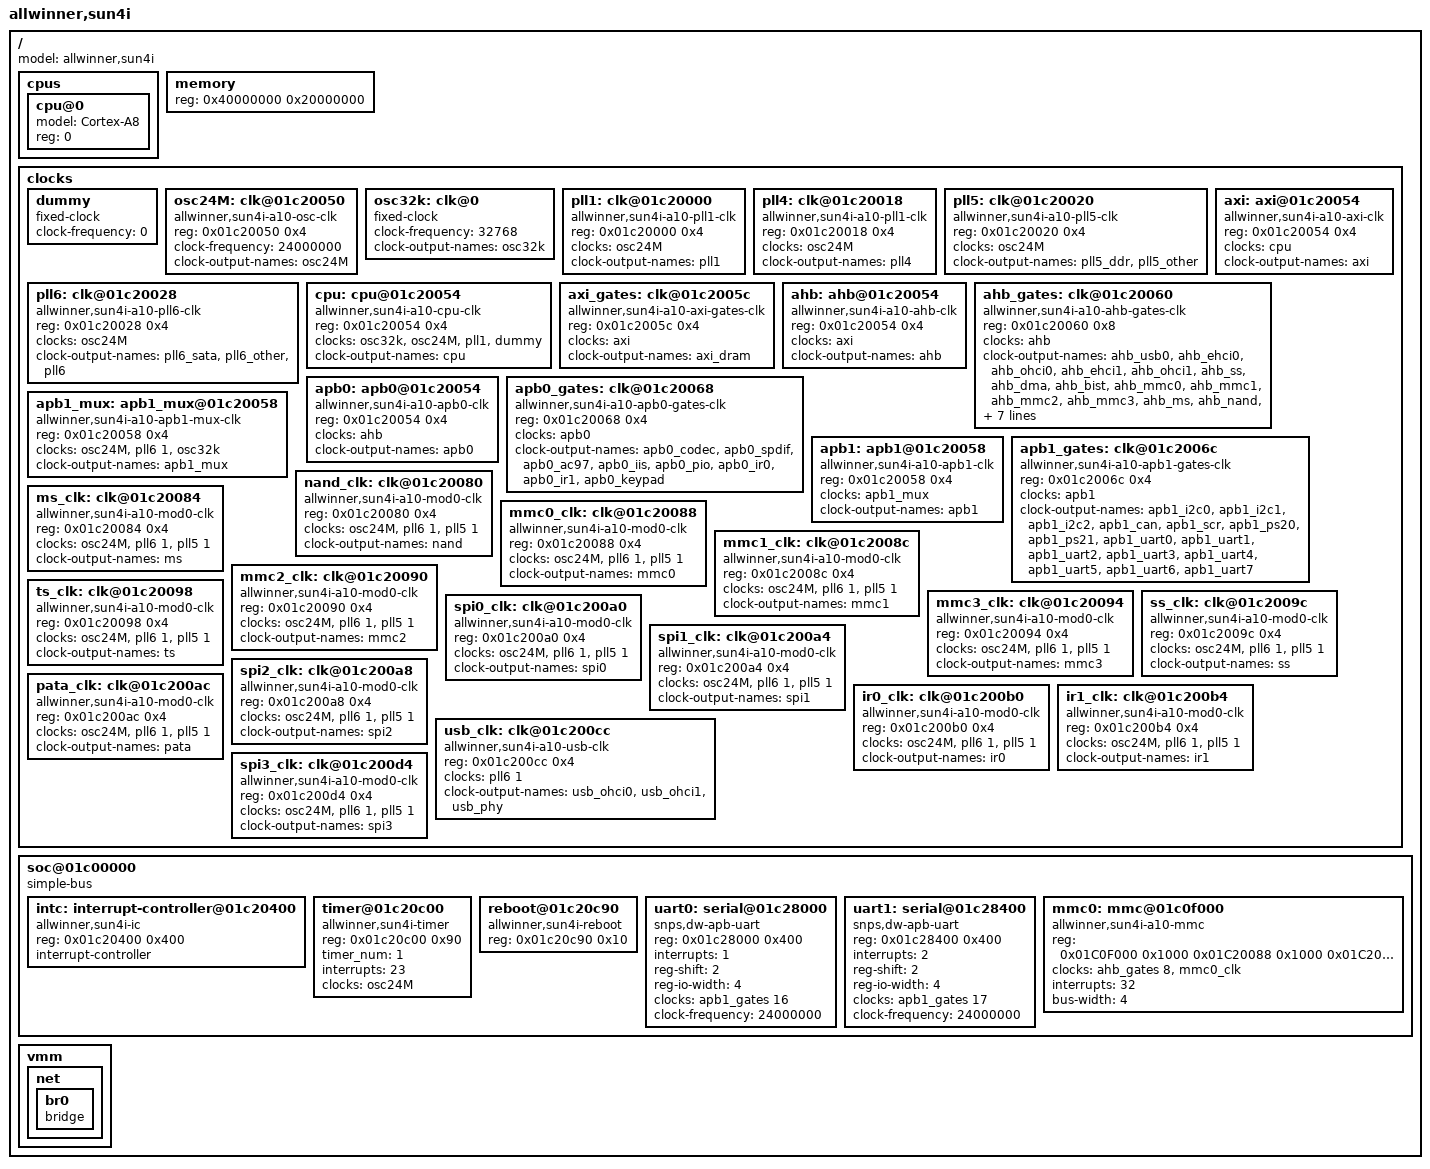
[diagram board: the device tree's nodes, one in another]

/ {
	#address-cells = <1>;
	#size-cells = <1>;
	model = "allwinner,sun4i";


	cpus {
		#address-cells = <1>;
		#size-cells = <0>;

		cpu@0 {
			device_type = "cpu";
			model = "Cortex-A8";
			reg = <0>;
		};
	};

	memory {
		device_type = "memory"; 
		reg = <0x40000000 0x20000000>; /* 512 MB */
	};

	clocks {
		#address-cells = <1>;
		#size-cells = <1>;
		ranges;

		/*
		 * This is a dummy clock, to be used as placeholder on
		 * other mux clocks when a specific parent clock is not
		 * yet implemented. It should be dropped when the driver
		 * is complete.
		 */
		dummy: dummy {
			#clock-cells = <0>;
			compatible = "fixed-clock";
			clock-frequency = <0>;
		};

		osc24M: clk@01c20050 {
			#clock-cells = <0>;
			compatible = "allwinner,sun4i-a10-osc-clk";
			reg = <0x01c20050 0x4>;
			clock-frequency = <24000000>;
			clock-output-names = "osc24M";
		};

		osc32k: clk@0 {
			#clock-cells = <0>;
			compatible = "fixed-clock";
			clock-frequency = <32768>;
			clock-output-names = "osc32k";
		};

		pll1: clk@01c20000 {
			#clock-cells = <0>;
			compatible = "allwinner,sun4i-a10-pll1-clk";
			reg = <0x01c20000 0x4>;
			clocks = <&osc24M>;
			clock-output-names = "pll1";
		};

		pll4: clk@01c20018 {
			#clock-cells = <0>;
			compatible = "allwinner,sun4i-a10-pll1-clk";
			reg = <0x01c20018 0x4>;
			clocks = <&osc24M>;
			clock-output-names = "pll4";
		};

		pll5: clk@01c20020 {
			#clock-cells = <1>;
			compatible = "allwinner,sun4i-a10-pll5-clk";
			reg = <0x01c20020 0x4>;
			clocks = <&osc24M>;
			clock-output-names = "pll5_ddr", "pll5_other";
		};

		pll6: clk@01c20028 {
			#clock-cells = <1>;
			compatible = "allwinner,sun4i-a10-pll6-clk";
			reg = <0x01c20028 0x4>;
			clocks = <&osc24M>;
			clock-output-names = "pll6_sata", "pll6_other", "pll6";
		};

		/* dummy is 200M */
		cpu: cpu@01c20054 {
			#clock-cells = <0>;
			compatible = "allwinner,sun4i-a10-cpu-clk";
			reg = <0x01c20054 0x4>;
			clocks = <&osc32k>, <&osc24M>, <&pll1>, <&dummy>;
			clock-output-names = "cpu";
		};

		axi: axi@01c20054 {
			#clock-cells = <0>;
			compatible = "allwinner,sun4i-a10-axi-clk";
			reg = <0x01c20054 0x4>;
			clocks = <&cpu>;
			clock-output-names = "axi";
		};

		axi_gates: clk@01c2005c {
			#clock-cells = <1>;
			compatible = "allwinner,sun4i-a10-axi-gates-clk";
			reg = <0x01c2005c 0x4>;
			clocks = <&axi>;
			clock-output-names = "axi_dram";
		};

		ahb: ahb@01c20054 {
			#clock-cells = <0>;
			compatible = "allwinner,sun4i-a10-ahb-clk";
			reg = <0x01c20054 0x4>;
			clocks = <&axi>;
			clock-output-names = "ahb";
		};

		ahb_gates: clk@01c20060 {
			#clock-cells = <1>;
			compatible = "allwinner,sun4i-a10-ahb-gates-clk";
			reg = <0x01c20060 0x8>;
			clocks = <&ahb>;
			clock-output-names = "ahb_usb0", "ahb_ehci0",
				"ahb_ohci0", "ahb_ehci1", "ahb_ohci1", "ahb_ss",
				"ahb_dma", "ahb_bist", "ahb_mmc0", "ahb_mmc1",
				"ahb_mmc2", "ahb_mmc3", "ahb_ms", "ahb_nand",
				"ahb_sdram", "ahb_ace",	"ahb_emac", "ahb_ts",
				"ahb_spi0", "ahb_spi1", "ahb_spi2", "ahb_spi3",
				"ahb_pata", "ahb_sata", "ahb_gps", "ahb_ve",
				"ahb_tvd", "ahb_tve0", "ahb_tve1", "ahb_lcd0",
				"ahb_lcd1", "ahb_csi0", "ahb_csi1", "ahb_hdmi",
				"ahb_de_be0", "ahb_de_be1", "ahb_de_fe0",
				"ahb_de_fe1", "ahb_mp", "ahb_mali400";
		};

		apb0: apb0@01c20054 {
			#clock-cells = <0>;
			compatible = "allwinner,sun4i-a10-apb0-clk";
			reg = <0x01c20054 0x4>;
			clocks = <&ahb>;
			clock-output-names = "apb0";
		};

		apb0_gates: clk@01c20068 {
			#clock-cells = <1>;
			compatible = "allwinner,sun4i-a10-apb0-gates-clk";
			reg = <0x01c20068 0x4>;
			clocks = <&apb0>;
			clock-output-names = "apb0_codec", "apb0_spdif",
				"apb0_ac97", "apb0_iis", "apb0_pio", "apb0_ir0",
				"apb0_ir1", "apb0_keypad";
		};

		apb1_mux: apb1_mux@01c20058 {
			#clock-cells = <0>;
			compatible = "allwinner,sun4i-a10-apb1-mux-clk";
			reg = <0x01c20058 0x4>;
			clocks = <&osc24M>, <&pll6 1>, <&osc32k>;
			clock-output-names = "apb1_mux";
		};

		apb1: apb1@01c20058 {
			#clock-cells = <0>;
			compatible = "allwinner,sun4i-a10-apb1-clk";
			reg = <0x01c20058 0x4>;
			clocks = <&apb1_mux>;
			clock-output-names = "apb1";
		};

		apb1_gates: clk@01c2006c {
			#clock-cells = <1>;
			compatible = "allwinner,sun4i-a10-apb1-gates-clk";
			reg = <0x01c2006c 0x4>;
			clocks = <&apb1>;
			clock-output-names = "apb1_i2c0", "apb1_i2c1",
				"apb1_i2c2", "apb1_can", "apb1_scr",
				"apb1_ps20", "apb1_ps21", "apb1_uart0",
				"apb1_uart1", "apb1_uart2", "apb1_uart3",
				"apb1_uart4", "apb1_uart5", "apb1_uart6",
				"apb1_uart7";
		};

		nand_clk: clk@01c20080 {
			#clock-cells = <0>;
			compatible = "allwinner,sun4i-a10-mod0-clk";
			reg = <0x01c20080 0x4>;
			clocks = <&osc24M>, <&pll6 1>, <&pll5 1>;
			clock-output-names = "nand";
		};

		ms_clk: clk@01c20084 {
			#clock-cells = <0>;
			compatible = "allwinner,sun4i-a10-mod0-clk";
			reg = <0x01c20084 0x4>;
			clocks = <&osc24M>, <&pll6 1>, <&pll5 1>;
			clock-output-names = "ms";
		};

		mmc0_clk: clk@01c20088 {
			#clock-cells = <0>;
			compatible = "allwinner,sun4i-a10-mod0-clk";
			reg = <0x01c20088 0x4>;
			clocks = <&osc24M>, <&pll6 1>, <&pll5 1>;
			clock-output-names = "mmc0";
		};

		mmc1_clk: clk@01c2008c {
			#clock-cells = <0>;
			compatible = "allwinner,sun4i-a10-mod0-clk";
			reg = <0x01c2008c 0x4>;
			clocks = <&osc24M>, <&pll6 1>, <&pll5 1>;
			clock-output-names = "mmc1";
		};

		mmc2_clk: clk@01c20090 {
			#clock-cells = <0>;
			compatible = "allwinner,sun4i-a10-mod0-clk";
			reg = <0x01c20090 0x4>;
			clocks = <&osc24M>, <&pll6 1>, <&pll5 1>;
			clock-output-names = "mmc2";
		};

		mmc3_clk: clk@01c20094 {
			#clock-cells = <0>;
			compatible = "allwinner,sun4i-a10-mod0-clk";
			reg = <0x01c20094 0x4>;
			clocks = <&osc24M>, <&pll6 1>, <&pll5 1>;
			clock-output-names = "mmc3";
		};

		ts_clk: clk@01c20098 {
			#clock-cells = <0>;
			compatible = "allwinner,sun4i-a10-mod0-clk";
			reg = <0x01c20098 0x4>;
			clocks = <&osc24M>, <&pll6 1>, <&pll5 1>;
			clock-output-names = "ts";
		};

		ss_clk: clk@01c2009c {
			#clock-cells = <0>;
			compatible = "allwinner,sun4i-a10-mod0-clk";
			reg = <0x01c2009c 0x4>;
			clocks = <&osc24M>, <&pll6 1>, <&pll5 1>;
			clock-output-names = "ss";
		};

		spi0_clk: clk@01c200a0 {
			#clock-cells = <0>;
			compatible = "allwinner,sun4i-a10-mod0-clk";
			reg = <0x01c200a0 0x4>;
			clocks = <&osc24M>, <&pll6 1>, <&pll5 1>;
			clock-output-names = "spi0";
		};

		spi1_clk: clk@01c200a4 {
			#clock-cells = <0>;
			compatible = "allwinner,sun4i-a10-mod0-clk";
			reg = <0x01c200a4 0x4>;
			clocks = <&osc24M>, <&pll6 1>, <&pll5 1>;
			clock-output-names = "spi1";
		};

		spi2_clk: clk@01c200a8 {
			#clock-cells = <0>;
			compatible = "allwinner,sun4i-a10-mod0-clk";
			reg = <0x01c200a8 0x4>;
			clocks = <&osc24M>, <&pll6 1>, <&pll5 1>;
			clock-output-names = "spi2";
		};

		pata_clk: clk@01c200ac {
			#clock-cells = <0>;
			compatible = "allwinner,sun4i-a10-mod0-clk";
			reg = <0x01c200ac 0x4>;
			clocks = <&osc24M>, <&pll6 1>, <&pll5 1>;
			clock-output-names = "pata";
		};

		ir0_clk: clk@01c200b0 {
			#clock-cells = <0>;
			compatible = "allwinner,sun4i-a10-mod0-clk";
			reg = <0x01c200b0 0x4>;
			clocks = <&osc24M>, <&pll6 1>, <&pll5 1>;
			clock-output-names = "ir0";
		};

		ir1_clk: clk@01c200b4 {
			#clock-cells = <0>;
			compatible = "allwinner,sun4i-a10-mod0-clk";
			reg = <0x01c200b4 0x4>;
			clocks = <&osc24M>, <&pll6 1>, <&pll5 1>;
			clock-output-names = "ir1";
		};

		usb_clk: clk@01c200cc {
			#clock-cells = <1>;
		        #reset-cells = <1>;
			compatible = "allwinner,sun4i-a10-usb-clk";
			reg = <0x01c200cc 0x4>;
			clocks = <&pll6 1>;
			clock-output-names = "usb_ohci0", "usb_ohci1", "usb_phy";
		};

		spi3_clk: clk@01c200d4 {
			#clock-cells = <0>;
			compatible = "allwinner,sun4i-a10-mod0-clk";
			reg = <0x01c200d4 0x4>;
			clocks = <&osc24M>, <&pll6 1>, <&pll5 1>;
			clock-output-names = "spi3";
		};
	};

	soc@01c00000 {
		compatible = "simple-bus";
		#address-cells = <1>;
		#size-cells = <1>;
		ranges;

		intc: interrupt-controller@01c20400 {
			compatible = "allwinner,sun4i-ic";
			reg = <0x01c20400 0x400>;
			interrupt-controller;
			#interrupt-cells = <1>;
		};

		timer@01c20c00 {
	      		device_type = "timer";
			compatible = "allwinner,sun4i-timer";
			reg = <0x01c20c00 0x90>;
			timer_num = <1>; /* Timer1 */
			interrupts = <23>;
			clocks = <&osc24M>;
		};

		reboot@01c20c90 {
			compatible = "allwinner,sun4i-reboot";
			reg = <0x01c20c90 0x10>;
		};

		uart0: serial@01c28000 {
			compatible = "snps,dw-apb-uart";
			reg = <0x01c28000 0x400>;
			interrupts = <1>;
			reg-shift = <2>;
			reg-io-width = <4>;
			clocks = <&apb1_gates 16>;
			/* Only for Xvisor */
			clock-frequency = <24000000>;
		};

		uart1: serial@01c28400 {
			compatible = "snps,dw-apb-uart";
			reg = <0x01c28400 0x400>;
			interrupts = <2>;
			reg-shift = <2>;
			reg-io-width = <4>;
			clocks = <&apb1_gates 17>;
			/* Only for Xvisor */
			clock-frequency = <24000000>;
		};

		mmc0: mmc@01c0f000 {
			compatible = "allwinner,sun4i-a10-mmc";
			reg =  <0x01C0F000 0x1000	/* registers */
				0x01C20088 0x1000	/* mclkbase */
				0x01C20060 0x1000	/* hclkbase */
				0x01C20020 0x1000	/* pll5cfg */
				0X01C20800 0x1000>;	/* gpiobase */
			clocks = <&ahb_gates 8>, <&mmc0_clk>;
			clock-names = "ahb", "mod";
			interrupts = <32>;
			bus-width = <4>;
		};
	};

	vmm {
		net {
			br0 {
				device_type = "netswitch";
				compatible = "bridge";
			};
		};
	};
};

/* Add guest templates */
/include/ "../../../common/guests/realview-pb-a8.dtsi"
/include/ "../../../common/guests/vexpress-a9x2.dtsi"

